# ATA5832 device description
Architecture: AVR8; Family: megaAVR
Registers are 8-bit, access not given, no defined reset value unless marked. A register's access mark holds for its fields unless they carry their own. Offsets are from the block's base; [hi:lo] are bit positions; {n}, {i} and the like mark numbered series; 'fields as' and 'values as' point back to an identical list.

## FRSYNC
Instances: FRSYNC 0x00
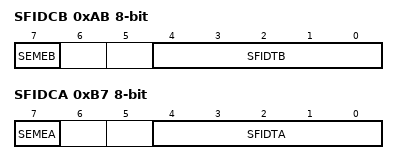
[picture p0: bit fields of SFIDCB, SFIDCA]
0xAB SFIDCB — Start-Frame ID Control for data path B
  [7] SEMEB — Serial mode enable for data path B
  [4:0] SFIDTB — Start-Frame ID threshold for data path B
0xAC SFIDLB — Start-Frame ID Length for data path B
  [5:0] SFIDLB
0xAD WUPTB — Wake-Up Pattern Threshold for data path B
  [4:0] WUPTB
0xAE WUPLB — Wake-Up Pattern Length for data path B
  [5:0] WUPLB
{0xAE+i} SFID{i}B (i=1..4) — Start-Frame ID byte {i} for data path B
{0xB2+i} WUP{i}B (i=1..4) — Wake-Up Pattern byte {i} for data path B
0xB7 SFIDCA — Start-Frame ID Control for data path A
  [7] SEMEA — Serial mode enable for data path A
  [4:0] SFIDTA — Start-Frame ID threshold for data path A
0xB8 SFIDLA — Start-Frame ID Length for data path A
  [5:0] SFIDLA
0xB9 WUPTA — Wake-Up Pattern Threshold for data path A
  [4:0] WUPTA
0xBA WUPLA — Wake-Up Pattern Length for data path A
  [5:0] WUPLA
{0xBA+i} SFID{i}A (i=1..4) — Start-Frame ID byte {i} for data path A
{0xBE+i} WUP{i}A (i=1..4) — Wake-Up Pattern byte {i} for data path A

## GPIOREGS
Instances: GPIOREGS 0x00
0x3A GPIOR0 — General Purpose I/O Register 0
{0x38+i} GPIOR{i} (i=3..6) — General Purpose I/O Register {i}
0x44 GPIOR1 — General Purpose I/O Register 1
0x45 GPIOR2 — General Purpose I/O Register 2

## IDSCAN
Instances: IDSCAN 0x00
{0x147+i} IDB{i} (i=0..3) — ID Byte {i}
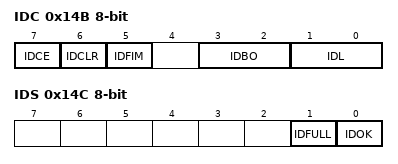
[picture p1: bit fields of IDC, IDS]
0x14B IDC — ID Configuration
  [7] IDCE — ID Check Execute
  [6] IDCLR — ID Clear
  [5] IDFIM — ID Full Interrupt Mask
  [3:2] IDBO — ID Byte Offset
  [1:0] IDL — ID Length
0x14C IDS — ID Status
  [1] IDFULL — ID Full Flag
  [0] IDOK — ID Scan Ok Flag

## INT
Instances: INT 0x00
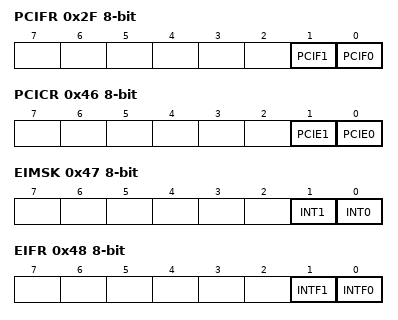
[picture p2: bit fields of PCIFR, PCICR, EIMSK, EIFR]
0x2F PCIFR — Pin change Interrupt flag Register
  [1] PCIF1 — Pin Change Interrupt Flag 1
  [0] PCIF0 — Pin Change Interrupt Flag 0
0x46 PCICR — Pin change Interrupt control Register
  [1] PCIE1 — Pin Change Interrupt Enable 1
  [0] PCIE0 — Pin Change Interrupt Enable 0
0x47 EIMSK — External Interrupt Mask Register
  [1] INT1 — External Interrupt Request 1 Enable
  [0] INT0 — External Interrupt Request 0 Enable
0x48 EIFR — External Interrupt Flag Register
  [1] INTF1 — External Interrupt Flag 1
  [0] INTF0 — External Interrupt Flag 0
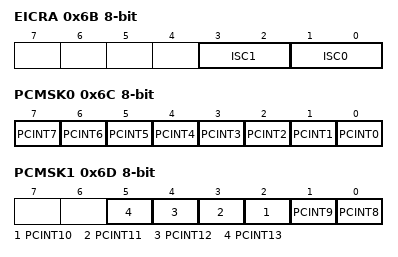
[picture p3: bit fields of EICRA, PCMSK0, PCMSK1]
0x6B EICRA — External Interrupt control Register
  [3:2] ISC1 — Interrupt Sense Control 1
    0=Low Level of INTX; 1=Logical Change of INTX; 2=Falling Edge of INTX; 3=Rising Edge of INTX
  [1:0] ISC0 — Interrupt Sense Control 0
    values as ISC1
0x6C PCMSK0 — Pin change Mask Register 0
  [n] PCINT{n} (n=0..7) — Pin Change Enable Mask bit {n}
0x6D PCMSK1 — Pin change Mask Register 1
  [n-8] PCINT{n} (n=8..13) — Pin Change Enable Mask bit {n}

## MEM
Instances: MEM 0x00
0x15A PGMST — Program Memory Status Register
  [4:0] PGMSYN — Program Memory Syndrome
0x15B EEST — EEPROM Status Register
  [3:0] EESYN — EEPROM Syndrome

## PORTB
Instances: PORTB 0x00
0x25 PINB — Port B Input Pins
0x26 DDRB — Port B Data Direction Register
0x27 PORTB — Port B Data Register

## PORTC
Instances: PORTC 0x00
0x28 PINC bits used 5:0 — Port C Input Pins
0x29 DDRC bits used 5:0 — Port C Data Direction Register
0x2A PORTC bits used 5:0 — Port C Data Register

## RSSIB
Instances: RSSIB 0x00
0x14D RSSAV — RSSI Average Value
0x14E RSSPK — RSSI Peak Value
0x14F RSSL — RSSI Low Threshold for Signal Check
0x150 RSSH — RSSI High Threshold for Signal Check
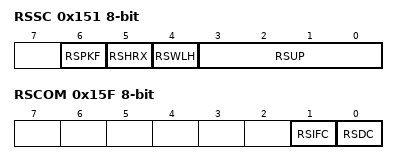
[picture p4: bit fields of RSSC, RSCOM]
0x151 RSSC — RSSI Configuration Register
  [6] RSPKF — RSSI Peak Values to SFIFO
  [5] RSHRX — RSSI High Band Reception
  [4] RSWLH — RSSI within Low and High Limits
  [3:0] RSUP — RSSI Update Period
0x15C RSIFG — RSSI High IF Amplifier Gain
0x15D RSLDV — RSSI Low Band Damping Value
0x15E RSHDV — RSSI High Band Damping Value
0x15F RSCOM — RSSI Compensation Register
  [1] RSIFC — RSSI IF Amplifier Compensation
  [0] RSDC — RSSI Damping Compensation
